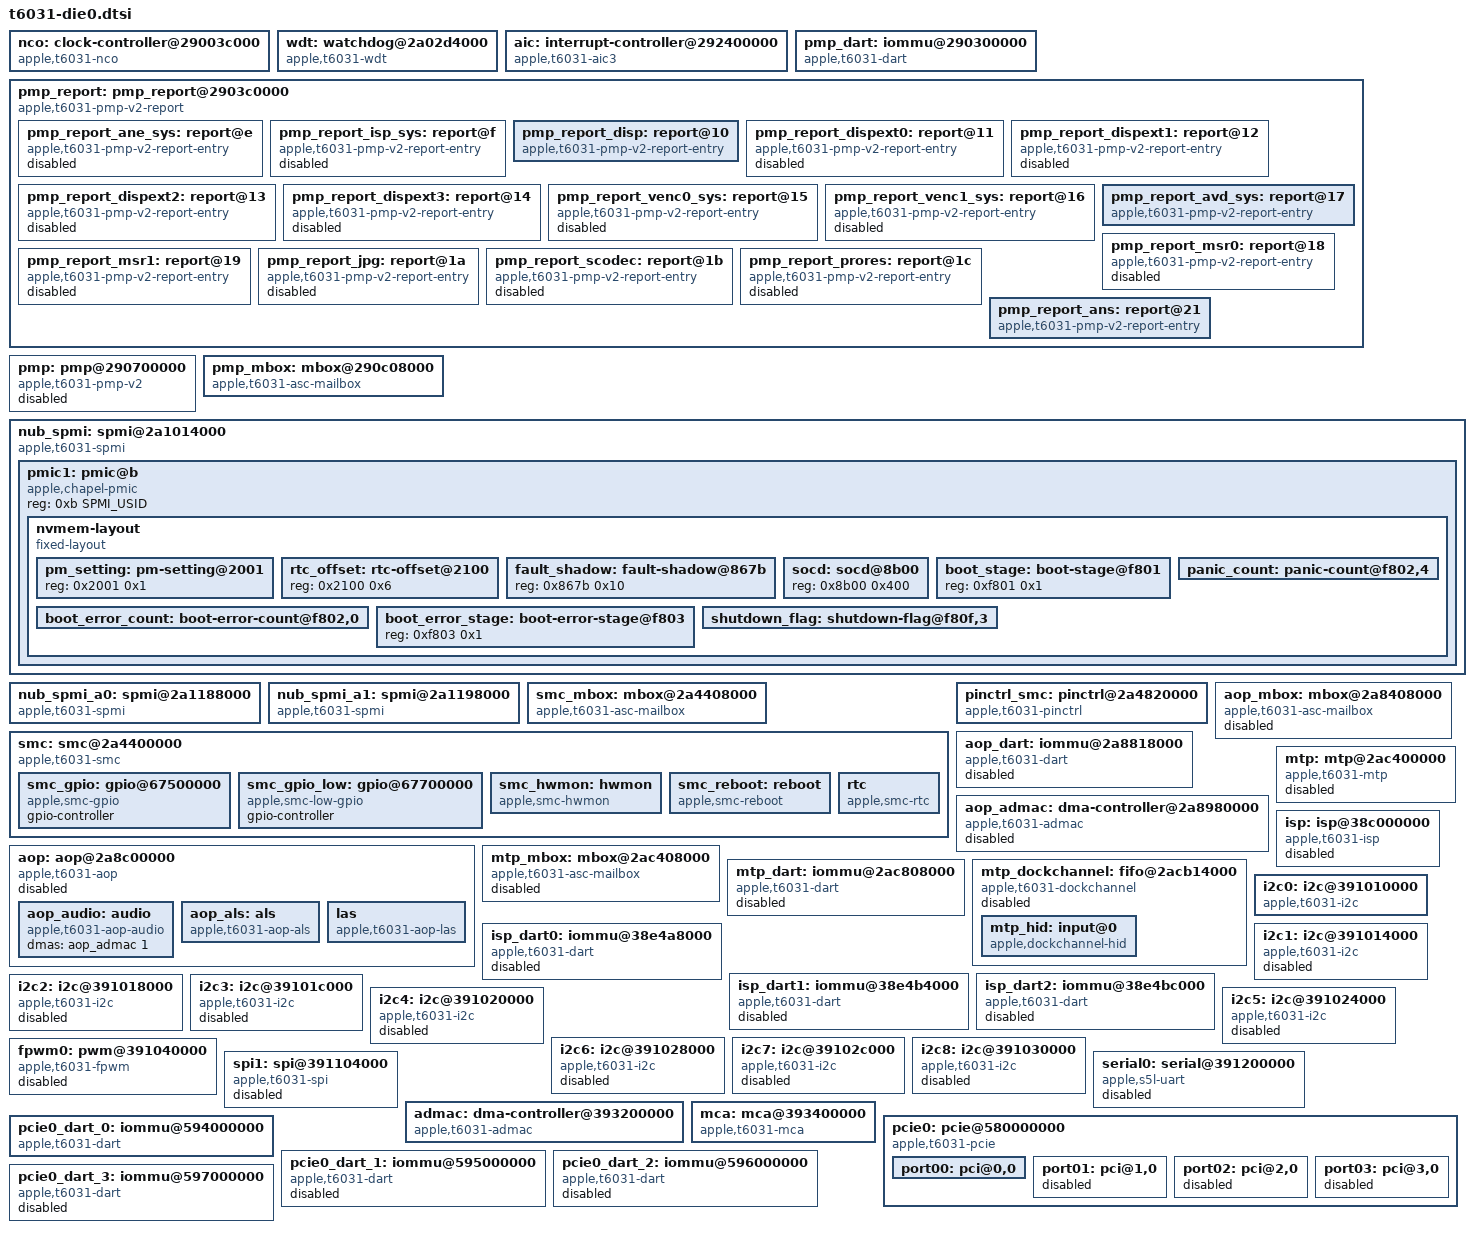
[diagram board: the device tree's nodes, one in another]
// SPDX-License-Identifier: GPL-2.0+ OR MIT
/*
 * Devices used on die 0 on the Apple T6032 "M3 Ultra" SoC and present on
 * Apple T6030 ("M3 Pro") and T6031 / T6034 ("M3 Max").
 *
 * Copyright The Asahi Linux Contributors
 */

	nco: clock-controller@29003c000 {
		compatible = "apple,t6031-nco", "apple,t8103-nco";
		reg = <0x2 0x9003c000 0x0 0x14000>;
		clocks = <&nco_clkref>;
		#clock-cells = <1>;
	};

	wdt: watchdog@2a02d4000 {
		compatible = "apple,t6031-wdt", "apple,t8103-wdt";
		reg = <0x2 0xa02d4000 0x0 0x4000>;
		clocks = <&clkref>;
		interrupt-parent = <&aic>;
		interrupts = <AIC_IRQ 0 718 IRQ_TYPE_LEVEL_HIGH>;
	};

	aic: interrupt-controller@292400000 {
		compatible = "apple,t6031-aic3", "apple,t8122-aic3";
		#interrupt-cells = <4>;
		interrupt-controller;

		reg = <0x00000002 0x92400000 0x00000000 0x1cc000>,
		      <0x00000002 0x92440000 0x00000000 0x4000>;
		reg-names = "core", "event";
		power-domains = <&ps_aic>;
	};

	pmp_dart: iommu@290300000 {
		compatible = "apple,t6031-dart", "apple,t8110-dart";
		reg = <0x2 0x90300000 0x0 0x4000>;
		#iommu-cells = <1>;
		interrupt-parent = <&aic>;
		interrupts = <AIC_IRQ 0 1184 IRQ_TYPE_LEVEL_HIGH>;
		power-domains = <&ps_pmp>;
	};

	pmp_report: pmp_report@2903c0000 {
		compatible = "apple,t6031-pmp-v2-report","apple,t6020-pmp-v2-report";
		reg = <0x2 0x903c0000 0x0 0x30000>;
		power-domains = <&ps_pms_sram>;
		#address-cells = <1>;
		#size-cells = <0>;

		pmp_report_ane_sys: report@e {
			compatible = "apple,t6031-pmp-v2-report-entry",
			             "apple,t6000-pmp-v2-report-entry";
			reg = <0xe>;
			label = "pmp-ane-sys";
			#power-domain-cells = <0>;
			power-domains = <&ps_ane_sys>;
			status = "disabled";
		};

		pmp_report_isp_sys: report@f {
			compatible = "apple,t6031-pmp-v2-report-entry",
			             "apple,t6000-pmp-v2-report-entry";
			reg = <0xf>;
			label = "pmp-isp-sys";
			#power-domain-cells = <0>;
			power-domains = <&ps_isp_sys>;
			status = "disabled";
		};

		pmp_report_disp: report@10 {
			compatible = "apple,t6031-pmp-v2-report-entry",
			             "apple,t6000-pmp-v2-report-entry";
			reg = <0x10>;
			label = "pmp-disp";
			#power-domain-cells = <0>;
			power-domains = <&ps_disp_fe>;
			apple,always-on;
		};

		pmp_report_dispext0: report@11 {
			compatible = "apple,t6031-pmp-v2-report-entry",
			             "apple,t6000-pmp-v2-report-entry";
			reg = <0x11>;
			label = "pmp-dispext0";
			#power-domain-cells = <0>;
			power-domains = <&ps_dispext0_fe>;
			status = "disabled";
		};

		pmp_report_dispext1: report@12 {
			compatible = "apple,t6031-pmp-v2-report-entry",
			             "apple,t6000-pmp-v2-report-entry";
			reg = <0x12>;
			label = "pmp-dispext1";
			#power-domain-cells = <0>;
			power-domains = <&ps_dispext1_fe>;
			status = "disabled";
		};

		pmp_report_dispext2: report@13 {
			compatible = "apple,t6031-pmp-v2-report-entry",
			             "apple,t6000-pmp-v2-report-entry";
			reg = <0x13>;
			label = "pmp-dispext2";
			#power-domain-cells = <0>;
			power-domains = <&ps_dispext2_fe>;
			status = "disabled";
		};

		pmp_report_dispext3: report@14 {
			compatible = "apple,t6031-pmp-v2-report-entry",
			             "apple,t6000-pmp-v2-report-entry";
			reg = <0x14>;
			label = "pmp-dispext3";
			#power-domain-cells = <0>;
			power-domains = <&ps_dispext3_fe>;
			status = "disabled";
		};

		pmp_report_venc0_sys: report@15 {
			compatible = "apple,t6031-pmp-v2-report-entry",
			             "apple,t6000-pmp-v2-report-entry";
			reg = <0x15>;
			label = "pmp-venc0-sys";
			#power-domain-cells = <0>;
			power-domains = <&ps_venc0_sys>;
			status = "disabled";
		};

		pmp_report_venc1_sys: report@16 {
			compatible = "apple,t6031-pmp-v2-report-entry",
			             "apple,t6000-pmp-v2-report-entry";
			reg = <0x16>;
			label = "pmp-venc1-sys";
			#power-domain-cells = <0>;
			power-domains = <&ps_venc1_sys>;
			status = "disabled";
		};

		pmp_report_avd_sys: report@17 {
			compatible = "apple,t6031-pmp-v2-report-entry",
			             "apple,t6000-pmp-v2-report-entry";
			reg = <0x17>;
			label = "pmp-avd-sys";
			#power-domain-cells = <0>;
			power-domains = <&ps_avd_sys>;
		};

		pmp_report_msr0: report@18 {
			compatible = "apple,t6031-pmp-v2-report-entry",
			        "apple,t6000-pmp-v2-report-entry";
			reg = <0x18>;
			label = "pmp-msr0";
			#power-domain-cells = <0>;
			power-domains = <&ps_msr0>;
			status = "disabled";
		};

		pmp_report_msr1: report@19 {
			compatible = "apple,t6031-pmp-v2-report-entry",
			             "apple,t6000-pmp-v2-report-entry";
			reg = <0x19>;
			label = "pmp-msr1";
			#power-domain-cells = <0>;
			power-domains = <&ps_msr1>;
			status = "disabled";
		};

		pmp_report_jpg: report@1a {
			compatible = "apple,t6031-pmp-v2-report-entry",
			             "apple,t6000-pmp-v2-report-entry";
			reg = <0x1a>;
			label = "pmp-jpg";
			#power-domain-cells = <0>;
			power-domains = <&ps_jpg>;
			status = "disabled";
		};

		pmp_report_scodec: report@1b {
			compatible = "apple,t6031-pmp-v2-report-entry",
			             "apple,t6000-pmp-v2-report-entry";
			reg = <0x1b>;
			label = "pmp-scodec";
			#power-domain-cells = <0>;
			power-domains = <&ps_scodec>;
			status = "disabled";
		};

		pmp_report_prores: report@1c {
			compatible = "apple,t6031-pmp-v2-report-entry",
			             "apple,t6000-pmp-v2-report-entry";
			reg = <0x1c>;
			label = "pmp-prores";
			#power-domain-cells = <0>;
			power-domains = <&ps_prores>;
			status = "disabled";
		};

		pmp_report_ans: report@21 {
			compatible = "apple,t6031-pmp-v2-report-entry",
			             "apple,t6000-pmp-v2-report-entry";
			reg = <0x21>;
			label = "pmp-ans";
			#power-domain-cells = <0>;
			power-domains = <&ps_ans>;
		};
	};

	pmp: pmp@290700000 {
		compatible = "apple,t6031-pmp-v2", "apple,t6000-pmp-v2";
		reg = <0x2 0x90700000 0x0 0x100000>,
		      <0x2 0x90c00000 0x0 0x4000>;
		reg-names = "pmp", "asc";
		mboxes = <&pmp_mbox>;
		mbox-names = "mbox";
		iommus = <&pmp_dart 0>;
		power-domains = <&ps_pmp>;
		status = "disabled";
	};

	pmp_mbox: mbox@290c08000 {
		compatible = "apple,t6031-asc-mailbox", "apple,asc-mailbox-v4";
		reg = <0x2 0x90c08000 0x0 0x4000>;
		interrupt-parent = <&aic>;
		interrupts = <AIC_IRQ 0 1180 IRQ_TYPE_LEVEL_HIGH>,
		             <AIC_IRQ 0 1181 IRQ_TYPE_LEVEL_HIGH>,
		             <AIC_IRQ 0 1182 IRQ_TYPE_LEVEL_HIGH>,
		             <AIC_IRQ 0 1183 IRQ_TYPE_LEVEL_HIGH>;
		interrupt-names = "send-empty", "send-not-empty",
		                  "recv-empty", "recv-not-empty";
		#mbox-cells = <0>;
		power-domains = <&ps_pmp>, <&ps_pms_sram>;
	};

	nub_spmi: spmi@2a1014000 {
		compatible = "apple,t6031-spmi", "apple,t8103-spmi";
		reg = <0x2 0xa1014000 0x0 0x100>;
		#address-cells = <2>;
		#size-cells = <0>;
		interrupt-parent = <&aic>;
		interrupts = <AIC_IRQ 0 723 IRQ_TYPE_LEVEL_HIGH>;

		pmic1: pmic@b {
			compatible = "apple,chapel-pmic", "apple,spmi-nvmem";
			reg = <0xb SPMI_USID>;

			nvmem-layout {
				compatible = "fixed-layout";
				#address-cells = <1>;
				#size-cells = <1>;

				pm_setting: pm-setting@2001 {
					reg = <0x2001 0x1>;
				};

				rtc_offset: rtc-offset@2100 {
					reg = <0x2100 0x6>;
				};

				fault_shadow: fault-shadow@867b {
					reg = <0x867b 0x10>;
				};

				socd: socd@8b00 {
					reg = <0x8b00 0x400>;
				};

				boot_stage: boot-stage@f801 {
					reg = <0xf801 0x1>;
				};

				boot_error_count: boot-error-count@f802,0 {
					reg = <0xf802 0x1>;
					bits = <0 4>;
				};

				panic_count: panic-count@f802,4 {
					reg = <0xf802 0x1>;
					bits = <4 4>;
				};

				boot_error_stage: boot-error-stage@f803 {
					reg = <0xf803 0x1>;
				};

				shutdown_flag: shutdown-flag@f80f,3 {
					reg = <0xf80f 0x1>;
					bits = <3 1>;
				};
			};
		};
	};

	nub_spmi_a0: spmi@2a1188000 {
		compatible = "apple,t6031-spmi", "apple,t8103-spmi";
		#address-cells = <2>;
		#size-cells = <0>;
		#interrupt-cells = <2>;
		interrupt-controller;

		reg = <0x2 0xa1188000 0x0 0x100>;
		interrupt-parent = <&aic>;
		interrupts = <AIC_IRQ 0 763 IRQ_TYPE_LEVEL_HIGH>;
		power-domains = <&ps_nub_spmi_a0>;
	};

	nub_spmi_a1: spmi@2a1198000 {
		compatible = "apple,t6031-spmi", "apple,t8103-spmi";
		#address-cells = <2>;
		#size-cells = <0>;
		#interrupt-cells = <2>;
		interrupt-controller;

		reg = <0x2 0xa1198000 0x0 0x100>;
		interrupt-parent = <&aic>;
		interrupts = <AIC_IRQ 0 765 IRQ_TYPE_LEVEL_HIGH>;
		power-domains = <&ps_nub_spmi_a1>;
	};

	smc_mbox: mbox@2a4408000 {
		compatible = "apple,t6031-asc-mailbox", "apple,asc-mailbox-v4";
		reg = <0x2 0xa4408000 0x0 0x4000>;
		interrupt-parent = <&aic>;
		interrupts = <AIC_IRQ 0 915 IRQ_TYPE_LEVEL_HIGH>,
			     <AIC_IRQ 0 916 IRQ_TYPE_LEVEL_HIGH>,
			     <AIC_IRQ 0 917 IRQ_TYPE_LEVEL_HIGH>,
			     <AIC_IRQ 0 918 IRQ_TYPE_LEVEL_HIGH>;
		interrupt-names = "send-empty", "send-not-empty",
			"recv-empty", "recv-not-empty";
		#mbox-cells = <0>;
	};

	smc: smc@2a4400000 {
		compatible = "apple,t6031-smc", "apple,t8103-smc";
		reg = <0x2 0xa4400000 0x0 0x4000>,
		      <0x2 0xa5e00000 0x0 0x100000>;
		reg-names = "smc", "sram";
		mboxes = <&smc_mbox>;

		smc_gpio: gpio@67500000 {
			compatible = "apple,smc-gpio";
			gpio-controller;
			#gpio-cells = <2>;
		};

		smc_gpio_low: gpio@67700000 {
			compatible = "apple,smc-low-gpio";
			gpio-controller;
			#gpio-cells = <2>;
		};

		smc_hwmon: hwmon {
			compatible = "apple,smc-hwmon";
		};

		smc_reboot: reboot {
			compatible = "apple,smc-reboot";
			nvmem-cells = <&shutdown_flag>, <&boot_stage>,
				<&boot_error_count>, <&panic_count>;
			nvmem-cell-names = "shutdown_flag", "boot_stage",
				"boot_error_count", "panic_count";
		};

		rtc {
			compatible = "apple,smc-rtc";
			nvmem-cells = <&rtc_offset>;
			nvmem-cell-names = "rtc_offset";
		};
	};

	pinctrl_smc: pinctrl@2a4820000 {
		compatible = "apple,t6031-pinctrl", "apple,t8103-pinctrl";
		reg = <0x2 0xa4820000 0x0 0x4000>;

		gpio-controller;
		#gpio-cells = <2>;
		gpio-ranges = <&pinctrl_smc 0 0 30>;
		apple,npins = <30>;

		interrupt-controller;
		#interrupt-cells = <2>;
		interrupt-parent = <&aic>;
		interrupts = <AIC_IRQ 0 904 IRQ_TYPE_LEVEL_HIGH>,
				<AIC_IRQ 0 905 IRQ_TYPE_LEVEL_HIGH>,
				<AIC_IRQ 0 906 IRQ_TYPE_LEVEL_HIGH>,
				<AIC_IRQ 0 907 IRQ_TYPE_LEVEL_HIGH>,
				<AIC_IRQ 0 908 IRQ_TYPE_LEVEL_HIGH>,
				<AIC_IRQ 0 909 IRQ_TYPE_LEVEL_HIGH>,
				<AIC_IRQ 0 910 IRQ_TYPE_LEVEL_HIGH>;
	};

	aop_mbox: mbox@2a8408000 {
		compatible = "apple,t6031-asc-mailbox", "apple,asc-mailbox-v4";
		reg = <0x2 0xa8408000 0x0 0x4000>;
		interrupt-parent = <&aic>;
		interrupts = <AIC_IRQ 0 612 IRQ_TYPE_LEVEL_HIGH>,
			<AIC_IRQ 0 613 IRQ_TYPE_LEVEL_HIGH>,
			<AIC_IRQ 0 614 IRQ_TYPE_LEVEL_HIGH>,
			<AIC_IRQ 0 615 IRQ_TYPE_LEVEL_HIGH>;
		interrupt-names = "send-empty", "send-not-empty",
			"recv-empty", "recv-not-empty";
		#mbox-cells = <0>;
		status = "disabled";
	};

	aop_dart: iommu@2a8818000 {
		compatible = "apple,t6031-dart", "apple,t8110-dart";
		reg = <0x2 0xa8818000 0x0 0x4000>;
		#iommu-cells = <1>;
		interrupt-parent = <&aic>;
		interrupts = <AIC_IRQ 0 627 IRQ_TYPE_LEVEL_HIGH>;
		status = "disabled";
		// apple,dma-range = <0x100 0x0 0x300 0x0>;
	};

	aop_admac: dma-controller@2a8980000 {
		compatible = "apple,t6031-admac", "apple,t8122-admac";
		reg = <0x2 0xa8980000 0x0 0x34000>;
		#dma-cells = <1>;
		dma-channels = <16>;
		interrupts-extended = <0>,
				      <0>,
				      <&aic AIC_IRQ 0 630 IRQ_TYPE_LEVEL_HIGH>,
				      <0>;
		iommus = <&aop_dart 10>;
		status = "disabled";
	};

	aop: aop@2a8c00000 {
		compatible = "apple,t6031-aop", "apple,t6020-aop";
		reg = <0x2 0xa8c00000 0x0 0x2a0000>,
		      <0x2 0xa8400000 0x0 0x6c000>;
		mboxes = <&aop_mbox>;
		mbox-names = "mbox";
		iommus = <&aop_dart 0>;

		status = "disabled";

		aop_audio: audio {
			compatible = "apple,t6031-aop-audio", "apple,t6030-aop-audio";
			dmas = <&aop_admac 1>;
			dma-names = "dma";
		};

		aop_als: als {
			compatible = "apple,t6031-aop-als", "apple,aop-als";
			// intentionally empty
		};

		las {
			compatible = "apple,t6031-aop-las", "apple,aop-las";
		};
	};

	mtp: mtp@2ac400000 {
		compatible = "apple,t6031-mtp", "apple,t8122-rtk-helper-asc4", "apple,mtp", "apple,rtk-helper-asc4";
		reg = <0x2 0xac400000 0x0 0x4000>,
		      <0x2 0xacc00000 0x0 0x100000>;
		reg-names = "asc", "sram";

		mboxes = <&mtp_mbox>;
		iommus = <&mtp_dart 1>;
		#helper-cells = <0>;

		status = "disabled";
	};

	mtp_mbox: mbox@2ac408000 {
		compatible = "apple,t6031-asc-mailbox", "apple,asc-mailbox-v4";
		reg = <0x2 0xac408000 0x0 0x4000>;

		interrupt-parent = <&aic>;
		interrupts = <AIC_IRQ 0 692 IRQ_TYPE_LEVEL_HIGH>,
			     <AIC_IRQ 0 693 IRQ_TYPE_LEVEL_HIGH>,
			     <AIC_IRQ 0 694 IRQ_TYPE_LEVEL_HIGH>,
			     <AIC_IRQ 0 695 IRQ_TYPE_LEVEL_HIGH>;
		interrupt-names = "send-empty", "send-not-empty",
			"recv-empty", "recv-not-empty";
		#mbox-cells = <0>;
		status = "disabled";
	};

	mtp_dart: iommu@2ac808000 {
		compatible = "apple,t6031-dart", "apple,t8110-dart";
		reg = <0x2 0xac808000 0x0 0x4000>;

		interrupt-parent = <&aic>;
		interrupts = <AIC_IRQ 0 675 IRQ_TYPE_LEVEL_HIGH>;

		#iommu-cells = <1>;

		status = "disabled";
	};

	mtp_dockchannel: fifo@2acb14000 {
		compatible = "apple,t6031-dockchannel", "apple,dockchannel";
		reg = <0x2 0xacb14000 0x0 0x4000>;
		reg-names = "irq";
		interrupt-parent = <&aic>;
		interrupts = <AIC_IRQ 0 676 IRQ_TYPE_LEVEL_HIGH>;

		ranges = <0 0x2 0xacb28000 0x20000>;
		nonposted-mmio;
		#address-cells = <1>;
		#size-cells = <1>;

		interrupt-controller;
		#interrupt-cells = <2>;

		status = "disabled";

		mtp_hid: input@0 {
			compatible = "apple,dockchannel-hid";
			reg = <0x0000 0x4000>,
			      <0x4000 0x4000>,
			      <0x8000 0x4000>,
			      <0xc000 0x4000>;
			reg-names = "rmt-config", "rmt-data", "config", "data";

			iommus = <&mtp_dart 1>;

			interrupt-parent = <&mtp_dockchannel>;
			interrupts = <2 IRQ_TYPE_LEVEL_HIGH>,
				<3 IRQ_TYPE_LEVEL_HIGH>;
			interrupt-names = "tx", "rx";

			apple,fifo-size = <0x800>;
			apple,helper-cpu = <&mtp>;
		};
	};

	isp_dart0: iommu@38e4a8000 {
		compatible = "apple,t6031-dart", "apple,t8110-dart";
		reg = <0x3 0x8e4a8000 0x0 0x4000>;
		#iommu-cells = <1>;
		interrupt-parent = <&aic>;
		interrupts = <AIC_IRQ 0 571 IRQ_TYPE_LEVEL_HIGH>;
		power-domains = <&ps_isp_sys>;

		apple,dma-range = <0x100 0x0 0x1 0x0>;
		status = "disabled";
	};

	isp_dart1: iommu@38e4b4000 {
		compatible = "apple,t6031-dart", "apple,t8110-dart";
		reg = <0x3 0x8e4b4000 0x0 0x4000>;
		#iommu-cells = <1>;
		interrupt-parent = <&aic>;
		interrupts = <AIC_IRQ 0 571 IRQ_TYPE_LEVEL_HIGH>;
		power-domains = <&ps_isp_sys>;

		apple,dma-range = <0x100 0x0 0x1 0x0>;
		status = "disabled";
	};

	isp_dart2: iommu@38e4bc000 {
		compatible = "apple,t6031-dart", "apple,t8110-dart";
		reg = <0x3 0x8e4bc000 0x0 0x4000>;
		#iommu-cells = <1>;
		interrupt-parent = <&aic>;
		interrupts = <AIC_IRQ 0 571 IRQ_TYPE_LEVEL_HIGH>;
		power-domains = <&ps_isp_sys>;

		apple,dma-range = <0x100 0x0 0x1 0x0>;
		status = "disabled";
	};

	isp: isp@38c000000 {
		compatible = "apple,t6031-isp";
		iommus = <&isp_dart0 0>, <&isp_dart1 0>, <&isp_dart2 0>;
		reg-names = "coproc", "mbox", "gpio", "mbox2";
		reg = <0x3 0x8c000000 0x0 0x2000000>,
			<0x3 0x8e4c4000 0x0 0x100>,
			<0x3 0x8e4c41d0 0x0 0x100>,
			<0x3 0x8e4c4458 0x0 0x100>;
		interrupt-parent = <&aic>;
		interrupts = <AIC_IRQ 0 566 IRQ_TYPE_LEVEL_HIGH>;
		power-domains = <&ps_isp_cpu>, <&ps_isp_fe>,
			<&ps_dprx>, <&ps_isp_secure>, <&ps_isp_be>,
			<&ps_isp_clr>;
		apple,dart-vm-size = <0x0 0xa0000000>;

		status = "disabled";
	};

	i2c0: i2c@391010000 {
		compatible = "apple,t6031-i2c", "apple,t8103-i2c";
		reg = <0x3 0x91010000 0x0 0x4000>;
		clocks = <&clkref>;
		interrupt-parent = <&aic>;
		interrupts = <AIC_IRQ 0 1326 IRQ_TYPE_LEVEL_HIGH>;
		pinctrl-0 = <&i2c0_pins>;
		pinctrl-names = "default";
		power-domains = <&ps_i2c0>;
		#address-cells = <0x1>;
		#size-cells = <0x0>;
	};

	i2c1: i2c@391014000 {
		compatible = "apple,t6031-i2c", "apple,t8103-i2c";
		reg = <0x3 0x91014000 0x0 0x4000>;
		clocks = <&clkref>;
		interrupt-parent = <&aic>;
		interrupts = <AIC_IRQ 0 1327 IRQ_TYPE_LEVEL_HIGH>;
		pinctrl-0 = <&i2c1_pins>;
		pinctrl-names = "default";
		power-domains = <&ps_i2c1>;
		#address-cells = <0x1>;
		#size-cells = <0x0>;
		status = "disabled";
	};

	i2c2: i2c@391018000 {
		compatible = "apple,t6031-i2c", "apple,t8103-i2c";
		reg = <0x3 0x91018000 0x0 0x4000>;
		clocks = <&clkref>;
		interrupt-parent = <&aic>;
		interrupts = <AIC_IRQ 0 1328 IRQ_TYPE_LEVEL_HIGH>;
		pinctrl-0 = <&i2c2_pins>;
		pinctrl-names = "default";
		power-domains = <&ps_i2c2>;
		#address-cells = <0x1>;
		#size-cells = <0x0>;
		status = "disabled";
	};

	i2c3: i2c@39101c000 {
		compatible = "apple,t6031-i2c", "apple,t8103-i2c";
		reg = <0x3 0x9101c000 0x0 0x4000>;
		clocks = <&clkref>;
		interrupt-parent = <&aic>;
		interrupts = <AIC_IRQ 0 1329 IRQ_TYPE_LEVEL_HIGH>;
		pinctrl-0 = <&i2c3_pins>;
		pinctrl-names = "default";
		power-domains = <&ps_i2c3>;
		#address-cells = <0x1>;
		#size-cells = <0x0>;
		status = "disabled";
	};

	i2c4: i2c@391020000 {
		compatible = "apple,t6031-i2c", "apple,t8103-i2c";
		reg = <0x3 0x91020000 0x0 0x4000>;
		clocks = <&clkref>;
		interrupt-parent = <&aic>;
		interrupts = <AIC_IRQ 0 1330 IRQ_TYPE_LEVEL_HIGH>;
		pinctrl-0 = <&i2c4_pins>;
		pinctrl-names = "default";
		power-domains = <&ps_i2c4>;
		#address-cells = <0x1>;
		#size-cells = <0x0>;
		status = "disabled";
	};

	i2c5: i2c@391024000 {
		compatible = "apple,t6031-i2c", "apple,t8103-i2c";
		reg = <0x3 0x91024000 0x0 0x4000>;
		clocks = <&clkref>;
		interrupt-parent = <&aic>;
		interrupts = <AIC_IRQ 0 1331 IRQ_TYPE_LEVEL_HIGH>;
		pinctrl-0 = <&i2c5_pins>;
		pinctrl-names = "default";
		power-domains = <&ps_i2c5>;
		#address-cells = <0x1>;
		#size-cells = <0x0>;
		status = "disabled";
	};

	i2c6: i2c@391028000 {
		compatible = "apple,t6031-i2c", "apple,t8103-i2c";
		reg = <0x3 0x91028000 0x0 0x4000>;
		clocks = <&clkref>;
		interrupt-parent = <&aic>;
		interrupts = <AIC_IRQ 0 1332 IRQ_TYPE_LEVEL_HIGH>;
		pinctrl-0 = <&i2c6_pins>;
		pinctrl-names = "default";
		power-domains = <&ps_i2c6>;
		#address-cells = <0x1>;
		#size-cells = <0x0>;
		status = "disabled";
	};

	i2c7: i2c@39102c000 {
		compatible = "apple,t6031-i2c", "apple,t8103-i2c";
		reg = <0x3 0x9102c000 0x0 0x4000>;
		clocks = <&clkref>;
		interrupt-parent = <&aic>;
		interrupts = <AIC_IRQ 0 1333 IRQ_TYPE_LEVEL_HIGH>;
		pinctrl-0 = <&i2c7_pins>;
		pinctrl-names = "default";
		power-domains = <&ps_i2c7>;
		#address-cells = <0x1>;
		#size-cells = <0x0>;
		status = "disabled";
	};

	i2c8: i2c@391030000 {
		compatible = "apple,t6031-i2c", "apple,t8103-i2c";
		reg = <0x3 0x91030000 0x0 0x4000>;
		clocks = <&clkref>;
		interrupt-parent = <&aic>;
		interrupts = <AIC_IRQ 0 1334 IRQ_TYPE_LEVEL_HIGH>;
		pinctrl-0 = <&i2c8_pins>;
		pinctrl-names = "default";
		power-domains = <&ps_i2c8>;
		#address-cells = <0x1>;
		#size-cells = <0x0>;
		status = "disabled";
	};

	fpwm0: pwm@391040000 {
		compatible = "apple,t6031-fpwm", "apple,s5l-fpwm";
		reg = <0x3 0x91040000 0x0 0x4000>;
		power-domains = <&ps_fpwm0>;
		clocks = <&clkref>;
		#pwm-cells = <2>;
		status = "disabled";
	};

	spi1: spi@391104000 {
		compatible = "apple,t6031-spi", "apple,t8103-spi";
		reg = <0x3 0x91104000 0x0 0x4000>;
		interrupt-parent = <&aic>;
		interrupts = <AIC_IRQ 0 1312 IRQ_TYPE_LEVEL_HIGH>;
		#address-cells = <1>;
		#size-cells = <0>;
		clocks = <&clk_200m>;
		pinctrl-0 = <&spi1_pins>;
		pinctrl-names = "default";
		power-domains = <&ps_spi1>;
		status = "disabled";
	};

	serial0: serial@391200000 {
		compatible = "apple,s5l-uart";
		reg = <0x3 0x91200000 0x0 0x4000>;
		reg-io-width = <4>;
		interrupt-parent = <&aic>;
		interrupts = <AIC_IRQ 0 1303 IRQ_TYPE_LEVEL_HIGH>;
		/*
		 * TODO: figure out the clocking properly, there may
		 * be a third selectable clock.
		 */
		clocks = <&clkref>, <&clkref>;
		clock-names = "uart", "clk_uart_baud0";
		power-domains = <&ps_uart0>;
		status = "disabled";
	};

	admac: dma-controller@393200000 {
		compatible = "apple,t6031-admac", "apple,t8122-admac";
		reg = <0x3 0x93200000 0x0 0x34000>;
		#dma-cells = <1>;
		dma-channels = <24>;
		interrupts-extended = <0>,
				      <&aic AIC_IRQ 0 1325 IRQ_TYPE_LEVEL_HIGH>,
				      <0>,
				      <0>;
		iommus = <&sio_dart 2>;
		power-domains = <&ps_sio_adma>;
		resets = <&ps_audio_p>;
	};

	mca: mca@393400000 {
		compatible = "apple,t6031-mca", "apple,t8103-mca";
		reg = <0x3 0x93400000 0x0 0x10000>,
		      <0x3 0x93300000 0x0 0x20000>;
		clocks = <&nco 0>, <&nco 1>, <&nco 2>, <&nco 3>;
		dmas = <&admac 0>, <&admac 1>, <&admac 2>, <&admac 3>,
		       <&admac 4>, <&admac 5>, <&admac 6>, <&admac 7>,
		       <&admac 8>, <&admac 9>, <&admac 10>, <&admac 11>,
		       <&admac 12>, <&admac 13>, <&admac 14>, <&admac 15>;
		dma-names = "tx0a", "rx0a", "tx0b", "rx0b",
			    "tx1a", "rx1a", "tx1b", "rx1b",
			    "tx2a", "rx2a", "tx2b", "rx2b",
			    "tx3a", "rx3a", "tx3b", "rx3b";
		interrupt-parent = <&aic>;
		interrupts = <AIC_IRQ 0 1318 IRQ_TYPE_LEVEL_HIGH>,
			     <AIC_IRQ 0 1319 IRQ_TYPE_LEVEL_HIGH>,
			     <AIC_IRQ 0 1320 IRQ_TYPE_LEVEL_HIGH>,
			     <AIC_IRQ 0 1321 IRQ_TYPE_LEVEL_HIGH>;
		power-domains = <&ps_audio_p>, <&ps_mca0>, <&ps_mca1>,
				<&ps_mca2>, <&ps_mca3>;
		resets = <&ps_audio_p>;
		#sound-dai-cells = <1>;
	};

	pcie0: pcie@580000000 {
		compatible = "apple,t6031-pcie", "apple,t6020-pcie";
		device_type = "pci";

		reg = <0x5 0x80000000 0x0 0x1000000>,	/* config */
		      <0x5 0x91000000 0x0 0x4000>,	/* rc */
		      <0x5 0x94008000 0x0 0x4000>,	/* port0 */
		      <0x5 0x95008000 0x0 0x4000>,	/* port1 */
		      <0x5 0x96008000 0x0 0x4000>,	/* port2 */
		      <0x5 0x97008000 0x0 0x4000>,	/* port3 */
		      <0x5 0x9e020000 0x0 0x4000>,	/* phy0 */
		      <0x5 0x9e024000 0x0 0x4000>,	/* phy1 */
		      <0x5 0x9e028000 0x0 0x4000>,	/* phy2 */
		      <0x5 0x9e02c000 0x0 0x4000>;	/* phy3 */
		reg-names = "config", "rc",
		            "port0", "port1", "port2", "port3",
		            "phy0", "phy1", "phy2", "phy3";

		interrupt-parent = <&aic>;
		interrupts = <AIC_IRQ 0 1491 IRQ_TYPE_LEVEL_HIGH>,
		             <AIC_IRQ 0 1500 IRQ_TYPE_LEVEL_HIGH>,
		             <AIC_IRQ 0 1509 IRQ_TYPE_LEVEL_HIGH>,
		             <AIC_IRQ 0 1518 IRQ_TYPE_LEVEL_HIGH>;

		msi-controller;
		msi-parent = <&pcie0>;
		msi-ranges = <&aic AIC_IRQ 0 1854 IRQ_TYPE_EDGE_RISING 32>;

		iommu-map = <0x100 &pcie0_dart_0 1 1>,
		            <0x200 &pcie0_dart_1 1 1>,
		            <0x300 &pcie0_dart_2 1 1>,
		            <0x400 &pcie0_dart_3 1 1>;
		iommu-map-mask = <0xff00>;

		bus-range = <0 4>;
		#address-cells = <3>;
		#size-cells = <2>;
		ranges = <0x43000000 0x5 0xa0000000 0x5 0xa0000000 0x0 0x20000000>,
		         <0x02000000 0x0 0xc0000000 0x5 0xc0000000 0x0 0x40000000>;

		power-domains = <&ps_apcie_sys_gp>;
		pinctrl-0 = <&pcie_pins>;
		pinctrl-names = "default";

		dma-coherent;

		port00: pci@0,0 {
			device_type = "pci";
			reg = <0x0 0x0 0x0 0x0 0x0>;
			reset-gpios = <&pinctrl_ap 4 GPIO_ACTIVE_LOW>;

			#address-cells = <3>;
			#size-cells = <2>;
			ranges;

			interrupt-controller;
			#interrupt-cells = <1>;

			interrupt-map-mask = <0 0 0 7>;
			interrupt-map = <0 0 0 1 &port00 0 0 0 0>,
			                <0 0 0 2 &port00 0 0 0 1>,
			                <0 0 0 3 &port00 0 0 0 2>,
			                <0 0 0 4 &port00 0 0 0 3>;
		};

		port01: pci@1,0 {
			device_type = "pci";
			reg = <0x800 0x0 0x0 0x0 0x0>;
			reset-gpios = <&pinctrl_ap 5 GPIO_ACTIVE_LOW>;

			#address-cells = <3>;
			#size-cells = <2>;
			ranges;

			interrupt-controller;
			#interrupt-cells = <1>;

			interrupt-map-mask = <0 0 0 7>;
			interrupt-map = <0 0 0 1 &port01 0 0 0 0>,
			                <0 0 0 2 &port01 0 0 0 1>,
			                <0 0 0 3 &port01 0 0 0 2>,
			                <0 0 0 4 &port01 0 0 0 3>;
			status = "disabled";
		};

		port02: pci@2,0 {
			device_type = "pci";
			reg = <0x1000 0x0 0x0 0x0 0x0>;
			reset-gpios = <&pinctrl_ap 6 GPIO_ACTIVE_LOW>;

			#address-cells = <3>;
			#size-cells = <2>;
			ranges;

			interrupt-controller;
			#interrupt-cells = <1>;

			interrupt-map-mask = <0 0 0 7>;
			interrupt-map = <0 0 0 1 &port02 0 0 0 0>,
			                <0 0 0 2 &port02 0 0 0 1>,
			                <0 0 0 3 &port02 0 0 0 2>,
			                <0 0 0 4 &port02 0 0 0 3>;
			status = "disabled";
		};

		port03: pci@3,0 {
			device_type = "pci";
			reg = <0x1800 0x0 0x0 0x0 0x0>;
			reset-gpios = <&pinctrl_ap 7 GPIO_ACTIVE_LOW>;

			#address-cells = <3>;
			#size-cells = <2>;
			ranges;

			interrupt-controller;
			#interrupt-cells = <1>;

			interrupt-map-mask = <0 0 0 7>;
			interrupt-map = <0 0 0 1 &port03 0 0 0 0>,
			                <0 0 0 2 &port03 0 0 0 1>,
			                <0 0 0 3 &port03 0 0 0 2>,
			                <0 0 0 4 &port03 0 0 0 3>;
			status = "disabled";
		};
	};

	pcie0_dart_0: iommu@594000000 {
		compatible = "apple,t6031-dart", "apple,t8110-dart";
		reg = <0x5 0x94000000 0x0 0x4000>;
		#iommu-cells = <1>;
		interrupt-parent = <&aic>;
		interrupts = <AIC_IRQ 0 1492 IRQ_TYPE_LEVEL_HIGH>;
		power-domains = <&ps_apcie_sys_gp>;
	};

	pcie0_dart_1: iommu@595000000 {
		compatible = "apple,t6031-dart", "apple,t8110-dart";
		reg = <0x5 0x95000000 0x0 0x4000>;
		#iommu-cells = <1>;
		interrupt-parent = <&aic>;
		interrupts = <AIC_IRQ 0 1501 IRQ_TYPE_LEVEL_HIGH>;
		power-domains = <&ps_apcie_sys_gp>;
		status = "disabled";
	};

	pcie0_dart_2: iommu@596000000 {
		compatible = "apple,t6031-dart", "apple,t8110-dart";
		reg = <0x5 0x96000000 0x0 0x4000>;
		#iommu-cells = <1>;
		interrupt-parent = <&aic>;
		interrupts = <AIC_IRQ 0 1510 IRQ_TYPE_LEVEL_HIGH>;
		power-domains = <&ps_apcie_sys_gp>;
		status = "disabled";
	};

	pcie0_dart_3: iommu@597000000 {
		compatible = "apple,t6031-dart", "apple,t8110-dart";
		reg = <0x5 0x97000000 0x0 0x4000>;
		#iommu-cells = <1>;
		interrupt-parent = <&aic>;
		interrupts = <AIC_IRQ 0 1519 IRQ_TYPE_LEVEL_HIGH>;
		power-domains = <&ps_apcie_sys_gp>;
		status = "disabled";
	};
